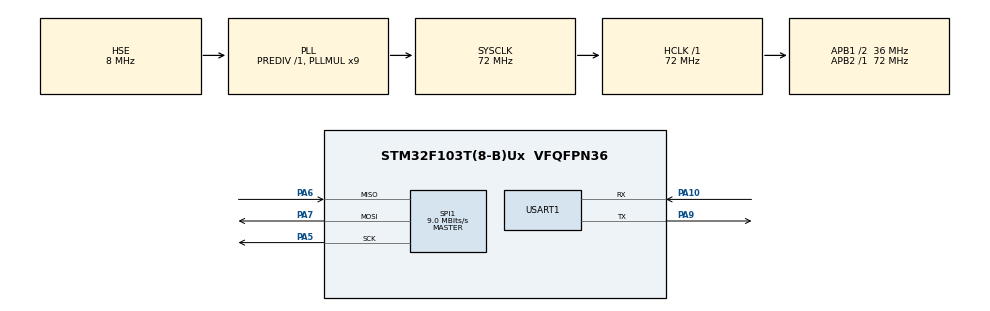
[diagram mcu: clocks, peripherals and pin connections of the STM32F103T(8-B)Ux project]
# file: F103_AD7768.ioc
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Mcu.Family=STM32F1
Mcu.Name=STM32F103T(8-B)Ux
Mcu.Package=VFQFPN36
NVIC.PriorityGroup=NVIC_PRIORITYGROUP_4
PA10.Mode=Asynchronous
PA10.Signal=USART1_RX
PA13.Mode=Serial_Wire
PA13.Signal=SYS_JTMS-SWDIO
PA14.Mode=Serial_Wire
PA14.Signal=SYS_JTCK-SWCLK
PA5.Mode=Full_Duplex_Master
PA5.Signal=SPI1_SCK
PA6.Mode=Full_Duplex_Master
PA6.Signal=SPI1_MISO
PA7.Mode=Full_Duplex_Master
PA7.Signal=SPI1_MOSI
PA9.Mode=Asynchronous
PA9.Signal=USART1_TX
PD0-OSC_IN.Mode=HSE-External-Oscillator
PD0-OSC_IN.Signal=RCC_OSC_IN
PD1-OSC_OUT.Mode=HSE-External-Oscillator
PD1-OSC_OUT.Signal=RCC_OSC_OUT
ProjectManager.HeapSize=0x200
ProjectManager.StackSize=0x400
ProjectManager.TargetToolchain=MDK-ARM V5
RCC.AHBFreq_Value=72000000
RCC.APB1CLKDivider=RCC_HCLK_DIV2
RCC.APB1Freq_Value=36000000
RCC.APB1TimFreq_Value=72000000
RCC.APB2Freq_Value=72000000
RCC.APB2TimFreq_Value=72000000
RCC.HCLKFreq_Value=72000000
RCC.PLLMUL=RCC_PLL_MUL9
RCC.PLLSourceVirtual=RCC_PLLSOURCE_HSE
RCC.SYSCLKFreq_VALUE=72000000
RCC.SYSCLKSource=RCC_SYSCLKSOURCE_PLLCLK
RCC.USBFreq_Value=72000000
SPI1.BaudRatePrescaler=SPI_BAUDRATEPRESCALER_8
SPI1.CLKPhase=SPI_PHASE_2EDGE
SPI1.CLKPolarity=SPI_POLARITY_HIGH
SPI1.CalculateBaudRate=9.0 MBits/s
SPI1.Direction=SPI_DIRECTION_2LINES
SPI1.Mode=SPI_MODE_MASTER
SPI1.VirtualType=VM_MASTER
USART1.VirtualMode=VM_ASYNC
board=custom

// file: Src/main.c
/* USER CODE BEGIN Header */
/**
  ******************************************************************************
  * @file           : main.c
  * @brief          : Main program body
  ******************************************************************************
  * @attention
  *
  * <h2><center>&copy; Copyright (c) 2019 STMicroelectronics.
  * All rights reserved.</center></h2>
  *
  * This software component is licensed by ST under BSD 3-Clause license,
  * the "License"; You may not use this file except in compliance with the
  * License. You may obtain a copy of the License at:
  *                        opensource.org/licenses/BSD-3-Clause
  *
  ******************************************************************************
  */
/* USER CODE END Header */

#include "main.h"

/* USER CODE BEGIN PD */
#define DEBUG
/* USER CODE END PD */

SPI_HandleTypeDef hspi1;

UART_HandleTypeDef huart1;

void SystemClock_Config(void);
static void MX_GPIO_Init(void);
static void MX_SPI1_Init(void);
static void MX_USART1_UART_Init(void);

int main(void)
{

  /* MCU Configuration--------------------------------------------------------*/

  /* Reset of all peripherals, Initializes the Flash interface and the Systick. */
  HAL_Init();

  /* Configure the system clock */
  SystemClock_Config();

  /* Initialize all configured peripherals */
  MX_GPIO_Init();
  MX_SPI1_Init();
  MX_USART1_UART_Init();

  /* Infinite loop */
  while (1)
  {
	printf("UART is sucessful!\n");
  }
}

void SystemClock_Config(void)
{
  RCC_OscInitTypeDef RCC_OscInitStruct = {0};
  RCC_ClkInitTypeDef RCC_ClkInitStruct = {0};

  /** Initializes the CPU, AHB and APB busses clocks
  */
  RCC_OscInitStruct.OscillatorType = RCC_OSCILLATORTYPE_HSE;
  RCC_OscInitStruct.HSEState = RCC_HSE_ON;
  RCC_OscInitStruct.HSEPredivValue = RCC_HSE_PREDIV_DIV1;
  RCC_OscInitStruct.HSIState = RCC_HSI_ON;
  RCC_OscInitStruct.PLL.PLLState = RCC_PLL_ON;
  RCC_OscInitStruct.PLL.PLLSource = RCC_PLLSOURCE_HSE;
  RCC_OscInitStruct.PLL.PLLMUL = RCC_PLL_MUL9;
  if (HAL_RCC_OscConfig(&RCC_OscInitStruct) != HAL_OK)
  {
    Error_Handler();
  }
  /** Initializes the CPU, AHB and APB busses clocks
  */
  RCC_ClkInitStruct.ClockType = RCC_CLOCKTYPE_HCLK|RCC_CLOCKTYPE_SYSCLK
                              |RCC_CLOCKTYPE_PCLK1|RCC_CLOCKTYPE_PCLK2;
  RCC_ClkInitStruct.SYSCLKSource = RCC_SYSCLKSOURCE_PLLCLK;
  RCC_ClkInitStruct.AHBCLKDivider = RCC_SYSCLK_DIV1;
  RCC_ClkInitStruct.APB1CLKDivider = RCC_HCLK_DIV2;
  RCC_ClkInitStruct.APB2CLKDivider = RCC_HCLK_DIV1;

  if (HAL_RCC_ClockConfig(&RCC_ClkInitStruct, FLASH_LATENCY_2) != HAL_OK)
  {
    Error_Handler();
  }
}

static void MX_SPI1_Init(void)
{

  /* SPI1 parameter configuration*/
  hspi1.Instance = SPI1;
  hspi1.Init.Mode = SPI_MODE_MASTER;
  hspi1.Init.Direction = SPI_DIRECTION_2LINES;
  hspi1.Init.DataSize = SPI_DATASIZE_8BIT;
  hspi1.Init.CLKPolarity = SPI_POLARITY_HIGH;
  hspi1.Init.CLKPhase = SPI_PHASE_2EDGE;
  hspi1.Init.NSS = SPI_NSS_HARD_OUTPUT;
  hspi1.Init.BaudRatePrescaler = SPI_BAUDRATEPRESCALER_8;
  hspi1.Init.FirstBit = SPI_FIRSTBIT_MSB;
  hspi1.Init.TIMode = SPI_TIMODE_DISABLE;
  hspi1.Init.CRCCalculation = SPI_CRCCALCULATION_DISABLE;
  hspi1.Init.CRCPolynomial = 10;
  if (HAL_SPI_Init(&hspi1) != HAL_OK)
  {
    Error_Handler();
  }

}

static void MX_USART1_UART_Init(void)
{

  huart1.Instance = USART1;
  huart1.Init.BaudRate = 115200;
  huart1.Init.WordLength = UART_WORDLENGTH_8B;
  huart1.Init.StopBits = UART_STOPBITS_1;
  huart1.Init.Parity = UART_PARITY_NONE;
  huart1.Init.Mode = UART_MODE_TX_RX;
  huart1.Init.HwFlowCtl = UART_HWCONTROL_NONE;
  huart1.Init.OverSampling = UART_OVERSAMPLING_16;
  if (HAL_UART_Init(&huart1) != HAL_OK)
  {
    Error_Handler();
  }

}

static void MX_GPIO_Init(void)
{

  /* GPIO Ports Clock Enable */
  __HAL_RCC_GPIOD_CLK_ENABLE();
  __HAL_RCC_GPIOA_CLK_ENABLE();

}

/* USER CODE BEGIN 4 */
#ifdef DEBUG
int fputc(int ch,FILE *f)
{
	HAL_UART_Transmit(&huart1,(uint8_t *)&ch,1,0xFFFF);
	return ch;
}
#endif
/* USER CODE END 4 */

void Error_Handler(void)
{
  /* USER CODE BEGIN Error_Handler_Debug */
  /* User can add his own implementation to report the HAL error return state */
#ifdef DEBUG
	printf("System init failed!\n");
#endif
  /* USER CODE END Error_Handler_Debug */
}

#ifdef  USE_FULL_ASSERT
/**
  * @brief  Reports the name of the source file and the source line number
  *         where the assert_param error has occurred.
  * @param  file: pointer to the source file name
  * @param  line: assert_param error line source number
  * @retval None
  */
void assert_failed(uint8_t *file, uint32_t line)
{
  /* USER CODE BEGIN 6 */
  /* User can add his own implementation to report the file name and line number,
#ifdef DEBUG
	printf("Wrong parameters value: file %s on line %d\r\n", file, line);
#endif
tex: printf("Wrong parameters value: file %s on line %d\r\n", file, line) */
  /* USER CODE END 6 */
}
#endif /* USE_FULL_ASSERT */

/************************ (C) COPYRIGHT STMicroelectronics *****END OF FILE****/
